VERSION ""

NS_ :

BS_:

BU_:

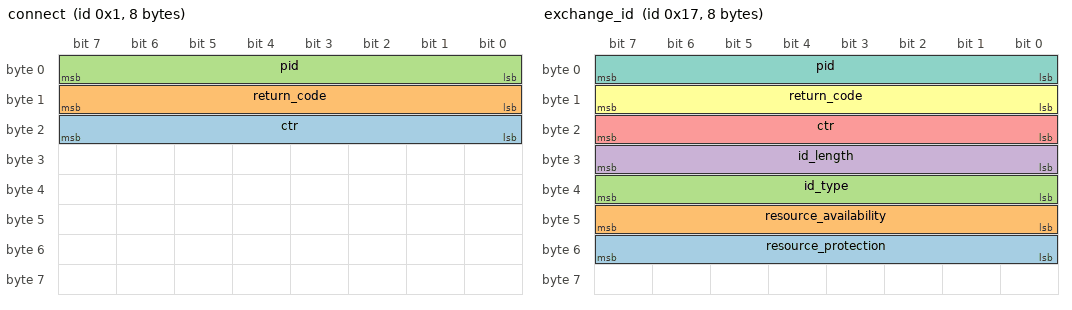
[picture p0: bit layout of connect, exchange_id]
BO_ 1 connect: 8 Vector__XXX
 SG_ ctr : 16|8@1+ (1,0) [0|0] "" Vector__XXX
 SG_ return_code : 8|8@1+ (1,0) [0|0] "" Vector__XXX
 SG_ pid : 0|8@1+ (1,0) [0|0] "" Vector__XXX

BO_ 23 exchange_id: 8 Vector__XXX
 SG_ resource_protection : 48|8@1+ (1,0) [0|0] "" Vector__XXX
 SG_ resource_availability : 40|8@1+ (1,0) [0|0] "" Vector__XXX
 SG_ id_type : 32|8@1+ (1,0) [0|0] "" Vector__XXX
 SG_ id_length : 24|8@1+ (1,0) [0|0] "" Vector__XXX
 SG_ ctr : 16|8@1+ (1,0) [0|0] "" Vector__XXX
 SG_ return_code : 8|8@1+ (1,0) [0|0] "" Vector__XXX
 SG_ pid : 0|8@1+ (1,0) [0|0] "" Vector__XXX

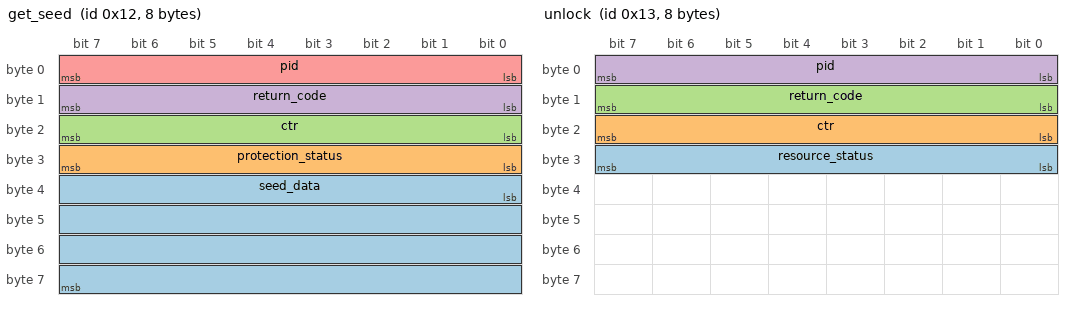
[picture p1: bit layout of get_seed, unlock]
BO_ 18 get_seed: 8 Vector__XXX
 SG_ seed_data : 32|32@1+ (1,0) [0|0] "" Vector__XXX
 SG_ protection_status : 24|8@1+ (1,0) [0|0] "" Vector__XXX
 SG_ ctr : 16|8@1+ (1,0) [0|0] "" Vector__XXX
 SG_ return_code : 8|8@1+ (1,0) [0|0] "" Vector__XXX
 SG_ pid : 0|8@1+ (1,0) [0|0] "" Vector__XXX

BO_ 19 unlock: 8 Vector__XXX
 SG_ resource_status : 24|8@1+ (1,0) [0|0] "" Vector__XXX
 SG_ ctr : 16|8@1+ (1,0) [0|0] "" Vector__XXX
 SG_ return_code : 8|8@1+ (1,0) [0|0] "" Vector__XXX
 SG_ pid : 0|8@1+ (1,0) [0|0] "" Vector__XXX

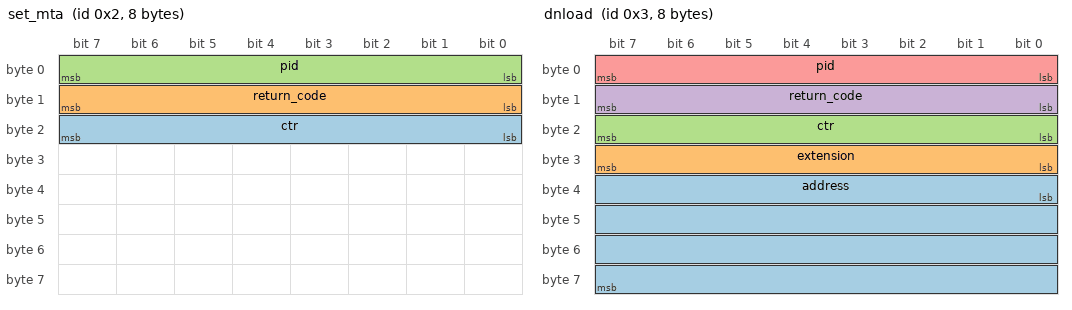
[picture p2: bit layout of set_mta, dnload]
BO_ 2 set_mta: 8 Vector__XXX
 SG_ ctr : 16|8@1+ (1,0) [0|0] "" Vector__XXX
 SG_ return_code : 8|8@1+ (1,0) [0|0] "" Vector__XXX
 SG_ pid : 0|8@1+ (1,0) [0|0] "" Vector__XXX

BO_ 3 dnload: 8 Vector__XXX
 SG_ address : 32|32@1+ (1,0) [0|0] "" Vector__XXX
 SG_ extension : 24|8@1+ (1,0) [0|0] "" Vector__XXX
 SG_ ctr : 16|8@1+ (1,0) [0|0] "" Vector__XXX
 SG_ return_code : 8|8@1+ (1,0) [0|0] "" Vector__XXX
 SG_ pid : 0|8@1+ (1,0) [0|0] "" Vector__XXX

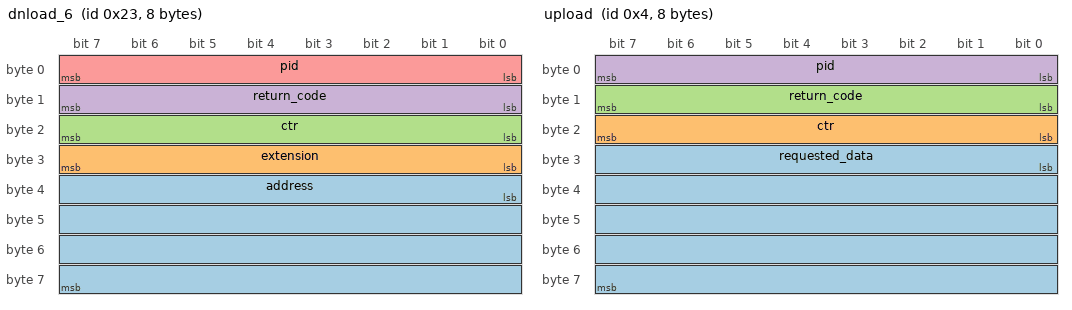
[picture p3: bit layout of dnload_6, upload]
BO_ 35 dnload_6: 8 Vector__XXX
 SG_ address : 32|32@1+ (1,0) [0|0] "" Vector__XXX
 SG_ extension : 24|8@1+ (1,0) [0|0] "" Vector__XXX
 SG_ ctr : 16|8@1+ (1,0) [0|0] "" Vector__XXX
 SG_ return_code : 8|8@1+ (1,0) [0|0] "" Vector__XXX
 SG_ pid : 0|8@1+ (1,0) [0|0] "" Vector__XXX

BO_ 4 upload: 8 Vector__XXX
 SG_ requested_data : 24|40@1+ (1,0) [0|0] "" Vector__XXX
 SG_ ctr : 16|8@1+ (1,0) [0|0] "" Vector__XXX
 SG_ return_code : 8|8@1+ (1,0) [0|0] "" Vector__XXX
 SG_ pid : 0|8@1+ (1,0) [0|0] "" Vector__XXX

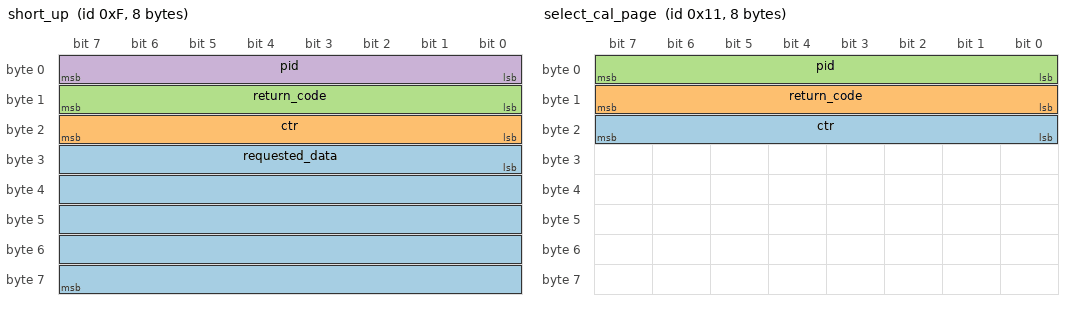
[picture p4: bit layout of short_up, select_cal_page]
BO_ 15 short_up: 8 Vector__XXX
 SG_ requested_data : 24|40@1+ (1,0) [0|0] "" Vector__XXX
 SG_ ctr : 16|8@1+ (1,0) [0|0] "" Vector__XXX
 SG_ return_code : 8|8@1+ (1,0) [0|0] "" Vector__XXX
 SG_ pid : 0|8@1+ (1,0) [0|0] "" Vector__XXX

BO_ 17 select_cal_page: 8 Vector__XXX
 SG_ ctr : 16|8@1+ (1,0) [0|0] "" Vector__XXX
 SG_ return_code : 8|8@1+ (1,0) [0|0] "" Vector__XXX
 SG_ pid : 0|8@1+ (1,0) [0|0] "" Vector__XXX

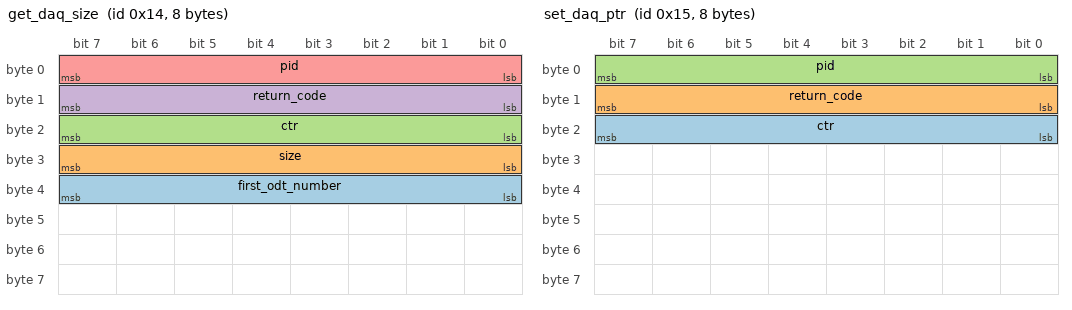
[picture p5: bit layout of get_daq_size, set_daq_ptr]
BO_ 20 get_daq_size: 8 Vector__XXX
 SG_ first_odt_number : 32|8@1+ (1,0) [0|0] "" Vector__XXX
 SG_ size : 24|8@1+ (1,0) [0|0] "" Vector__XXX
 SG_ ctr : 16|8@1+ (1,0) [0|0] "" Vector__XXX
 SG_ return_code : 8|8@1+ (1,0) [0|0] "" Vector__XXX
 SG_ pid : 0|8@1+ (1,0) [0|0] "" Vector__XXX

BO_ 21 set_daq_ptr: 8 Vector__XXX
 SG_ ctr : 16|8@1+ (1,0) [0|0] "" Vector__XXX
 SG_ return_code : 8|8@1+ (1,0) [0|0] "" Vector__XXX
 SG_ pid : 0|8@1+ (1,0) [0|0] "" Vector__XXX

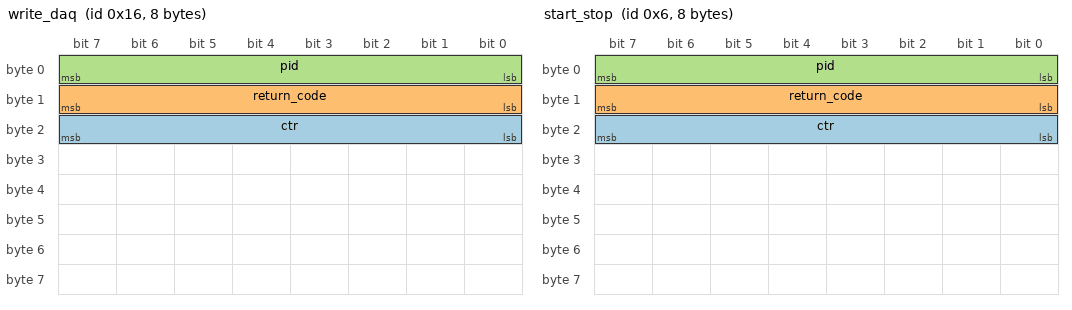
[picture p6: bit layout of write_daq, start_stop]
BO_ 22 write_daq: 8 Vector__XXX
 SG_ ctr : 16|8@1+ (1,0) [0|0] "" Vector__XXX
 SG_ return_code : 8|8@1+ (1,0) [0|0] "" Vector__XXX
 SG_ pid : 0|8@1+ (1,0) [0|0] "" Vector__XXX

BO_ 6 start_stop: 8 Vector__XXX
 SG_ ctr : 16|8@1+ (1,0) [0|0] "" Vector__XXX
 SG_ return_code : 8|8@1+ (1,0) [0|0] "" Vector__XXX
 SG_ pid : 0|8@1+ (1,0) [0|0] "" Vector__XXX

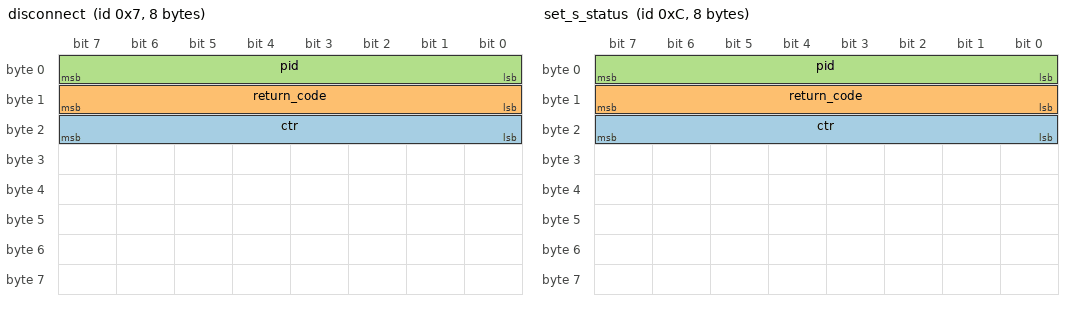
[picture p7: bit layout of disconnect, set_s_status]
BO_ 7 disconnect: 8 Vector__XXX
 SG_ ctr : 16|8@1+ (1,0) [0|0] "" Vector__XXX
 SG_ return_code : 8|8@1+ (1,0) [0|0] "" Vector__XXX
 SG_ pid : 0|8@1+ (1,0) [0|0] "" Vector__XXX

BO_ 12 set_s_status: 8 Vector__XXX
 SG_ ctr : 16|8@1+ (1,0) [0|0] "" Vector__XXX
 SG_ return_code : 8|8@1+ (1,0) [0|0] "" Vector__XXX
 SG_ pid : 0|8@1+ (1,0) [0|0] "" Vector__XXX

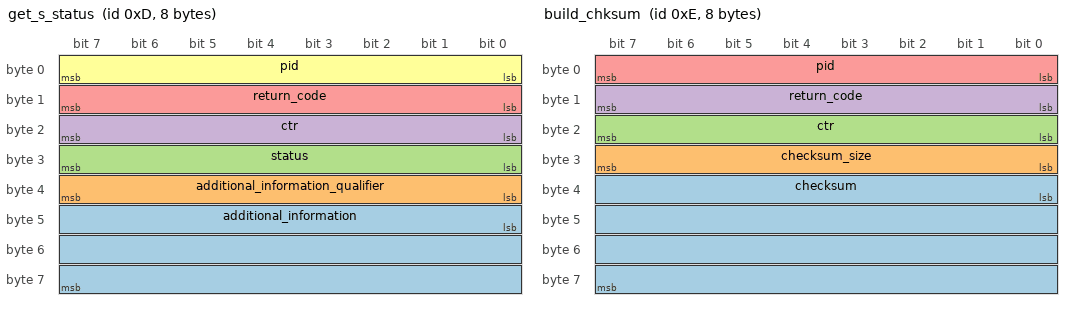
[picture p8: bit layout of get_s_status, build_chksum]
BO_ 13 get_s_status: 8 Vector__XXX
 SG_ additional_information : 40|24@1+ (1,0) [0|0] "" Vector__XXX
 SG_ additional_information_qualifier : 32|8@1+ (1,0) [0|0] "" Vector__XXX
 SG_ status : 24|8@1+ (1,0) [0|0] "" Vector__XXX
 SG_ ctr : 16|8@1+ (1,0) [0|0] "" Vector__XXX
 SG_ return_code : 8|8@1+ (1,0) [0|0] "" Vector__XXX
 SG_ pid : 0|8@1+ (1,0) [0|0] "" Vector__XXX

BO_ 14 build_chksum: 8 Vector__XXX
 SG_ checksum : 32|32@1+ (1,0) [0|0] "" Vector__XXX
 SG_ checksum_size : 24|8@1+ (1,0) [0|0] "" Vector__XXX
 SG_ ctr : 16|8@1+ (1,0) [0|0] "" Vector__XXX
 SG_ return_code : 8|8@1+ (1,0) [0|0] "" Vector__XXX
 SG_ pid : 0|8@1+ (1,0) [0|0] "" Vector__XXX

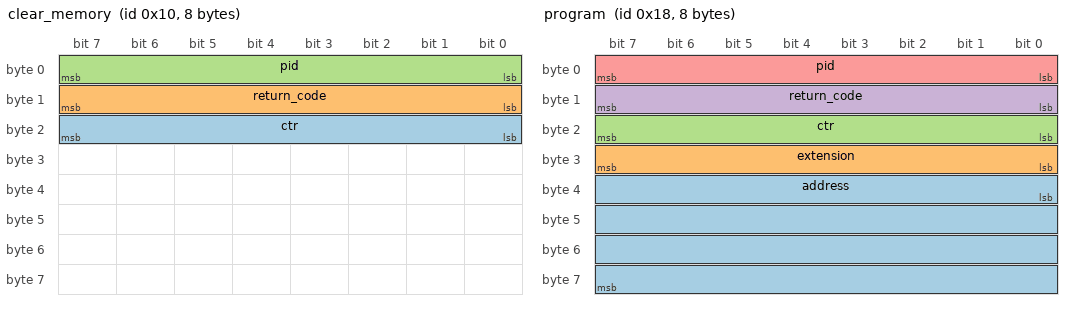
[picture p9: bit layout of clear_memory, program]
BO_ 16 clear_memory: 8 Vector__XXX
 SG_ ctr : 16|8@1+ (1,0) [0|0] "" Vector__XXX
 SG_ return_code : 8|8@1+ (1,0) [0|0] "" Vector__XXX
 SG_ pid : 0|8@1+ (1,0) [0|0] "" Vector__XXX

BO_ 24 program: 8 Vector__XXX
 SG_ address : 32|32@1+ (1,0) [0|0] "" Vector__XXX
 SG_ extension : 24|8@1+ (1,0) [0|0] "" Vector__XXX
 SG_ ctr : 16|8@1+ (1,0) [0|0] "" Vector__XXX
 SG_ return_code : 8|8@1+ (1,0) [0|0] "" Vector__XXX
 SG_ pid : 0|8@1+ (1,0) [0|0] "" Vector__XXX

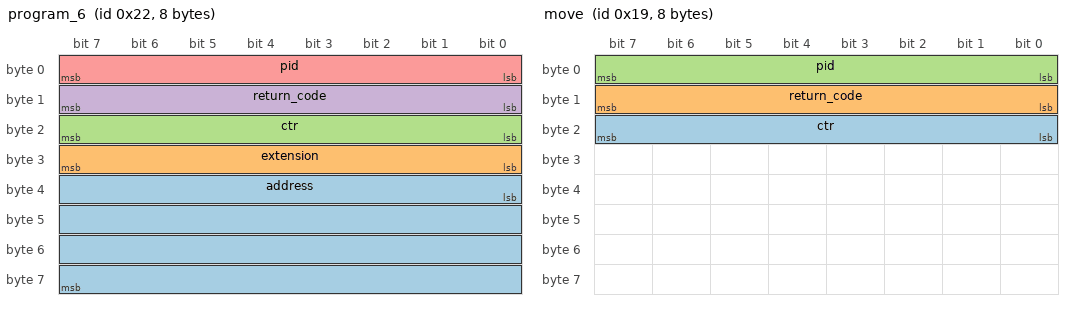
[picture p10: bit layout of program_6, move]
BO_ 34 program_6: 8 Vector__XXX
 SG_ address : 32|32@1+ (1,0) [0|0] "" Vector__XXX
 SG_ extension : 24|8@1+ (1,0) [0|0] "" Vector__XXX
 SG_ ctr : 16|8@1+ (1,0) [0|0] "" Vector__XXX
 SG_ return_code : 8|8@1+ (1,0) [0|0] "" Vector__XXX
 SG_ pid : 0|8@1+ (1,0) [0|0] "" Vector__XXX

BO_ 25 move: 8 Vector__XXX
 SG_ ctr : 16|8@1+ (1,0) [0|0] "" Vector__XXX
 SG_ return_code : 8|8@1+ (1,0) [0|0] "" Vector__XXX
 SG_ pid : 0|8@1+ (1,0) [0|0] "" Vector__XXX

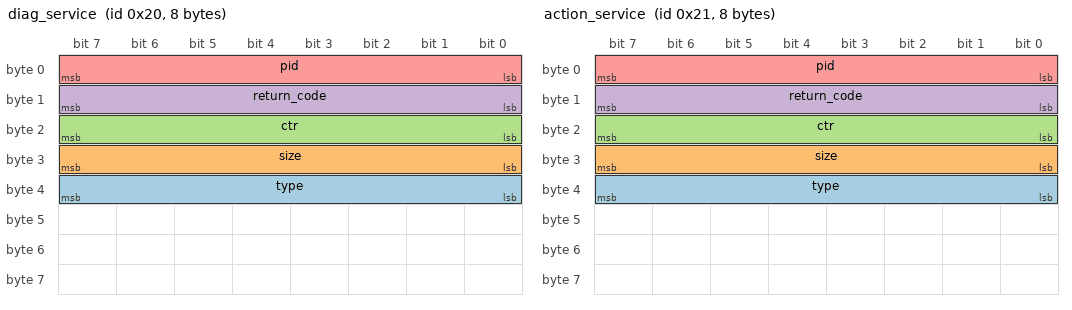
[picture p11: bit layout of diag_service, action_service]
BO_ 32 diag_service: 8 Vector__XXX
 SG_ type : 32|8@1+ (1,0) [0|0] "" Vector__XXX
 SG_ size : 24|8@1+ (1,0) [0|0] "" Vector__XXX
 SG_ ctr : 16|8@1+ (1,0) [0|0] "" Vector__XXX
 SG_ return_code : 8|8@1+ (1,0) [0|0] "" Vector__XXX
 SG_ pid : 0|8@1+ (1,0) [0|0] "" Vector__XXX

BO_ 33 action_service: 8 Vector__XXX
 SG_ type : 32|8@1+ (1,0) [0|0] "" Vector__XXX
 SG_ size : 24|8@1+ (1,0) [0|0] "" Vector__XXX
 SG_ ctr : 16|8@1+ (1,0) [0|0] "" Vector__XXX
 SG_ return_code : 8|8@1+ (1,0) [0|0] "" Vector__XXX
 SG_ pid : 0|8@1+ (1,0) [0|0] "" Vector__XXX

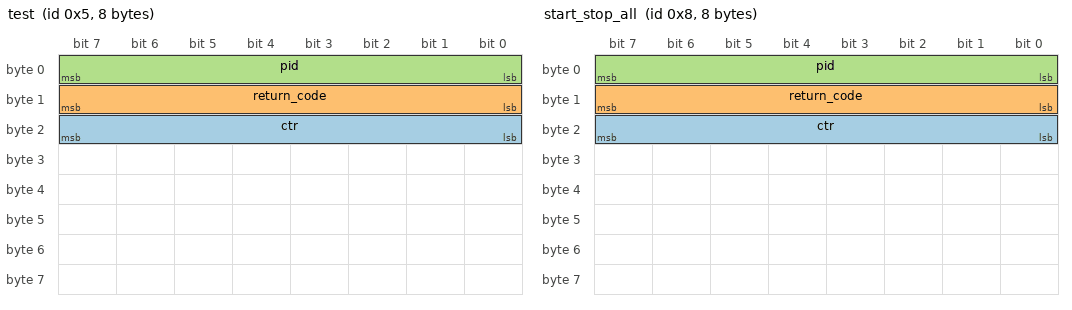
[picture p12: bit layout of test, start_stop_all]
BO_ 5 test: 8 Vector__XXX
 SG_ ctr : 16|8@1+ (1,0) [0|0] "" Vector__XXX
 SG_ return_code : 8|8@1+ (1,0) [0|0] "" Vector__XXX
 SG_ pid : 0|8@1+ (1,0) [0|0] "" Vector__XXX

BO_ 8 start_stop_all: 8 Vector__XXX
 SG_ ctr : 16|8@1+ (1,0) [0|0] "" Vector__XXX
 SG_ return_code : 8|8@1+ (1,0) [0|0] "" Vector__XXX
 SG_ pid : 0|8@1+ (1,0) [0|0] "" Vector__XXX

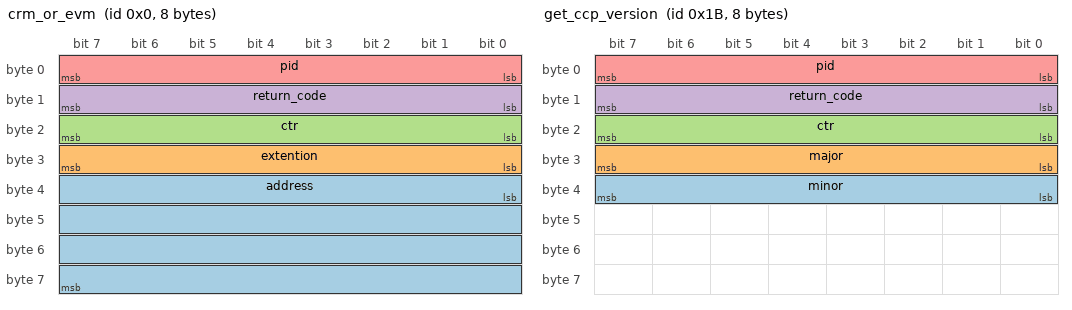
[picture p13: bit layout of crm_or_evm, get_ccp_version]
BO_ 0 crm_or_evm: 8 Vector__XXX
 SG_ address : 32|32@1+ (1,0) [0|0] "" Vector__XXX
 SG_ extention : 24|8@1+ (1,0) [0|0] "" Vector__XXX
 SG_ ctr : 16|8@1+ (1,0) [0|0] "" Vector__XXX
 SG_ return_code : 8|8@1+ (1,0) [0|0] "" Vector__XXX
 SG_ pid : 0|8@1+ (1,0) [0|0] "" Vector__XXX

BO_ 27 get_ccp_version: 8 Vector__XXX
 SG_ minor : 32|8@1+ (1,0) [0|0] "" Vector__XXX
 SG_ major : 24|8@1+ (1,0) [0|0] "" Vector__XXX
 SG_ ctr : 16|8@1+ (1,0) [0|0] "" Vector__XXX
 SG_ return_code : 8|8@1+ (1,0) [0|0] "" Vector__XXX
 SG_ pid : 0|8@1+ (1,0) [0|0] "" Vector__XXX
